# psoc4hv144k register map
Vendor: Infineon Technologies; Series: PSOC4HV144K; File version: 1.0
CPU: CM0PLUS r0p1, little endian, MPU, no FPU, VTOR, 2 interrupt priority bits, 25 interrupts
Registers are 32-bit, read-write, reset 0x0 unless marked. A register's access mark holds for its fields unless they carry their own. Offsets are from the block's base; [hi:lo] are bit positions; {n}, {i} and the like mark numbered series.

## HVSS — High Voltage Subsystem
Base 0x40060000
0x00 HVREG_STATUS ro
  [0] PWR_GOOD — High if regulator is settled and operating within normal limits
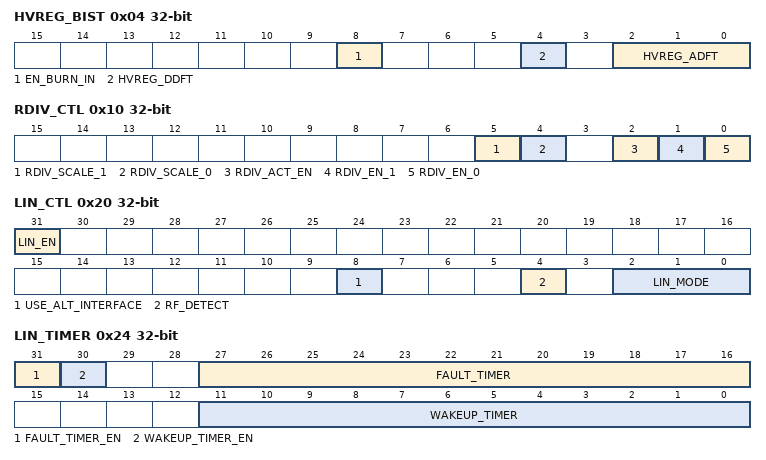
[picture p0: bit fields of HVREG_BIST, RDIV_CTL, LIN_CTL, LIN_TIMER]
0x04 HVREG_BIST
  [8] EN_BURN_IN — Enable burn-in test mode with Vccd(1.8V) domain
  [4] HVREG_DDFT — Enable HVREG DDFT outputs to DDFT interface when '1' (PG on ddft0, '0' on ddft1)
  [2:0] HVREG_ADFT — Controls ADFT switches
    0=NORMAL (Normal operation, amuxbus_a=Z); 1=BIAS_CIRCUIT_CURRENT_MONITOR (Bias current monitor (NMOS drain) on amuxbus_a); {v}=RSVD_{v} (N/A) (v=2..7)
0x10 RDIV_CTL — Resistor Attenuator Control
  [5] RDIV_SCALE_1 — VS1 attenuation 0=16X attenuation 1=24X attenuation
  [4] RDIV_SCALE_0 — VS0 attenuation 0=16X attenuation 1=24X attenuation
  [2] RDIV_ACT_EN — Power modes where RDIV is enabled 0=Enable in Active and Deep-Sleep modes 1=Enable in Active mode only
  [1] RDIV_EN_1 — Enable VS1 0=Disabled 1=Enabled during power modes selected by RDIVacten
  [0] RDIV_EN_0 — Enable VS0 0=Disabled 1=Enabled during power modes selected by RDIVacten
0x20 LIN_CTL — LIN Phy Control
  [31] LIN_EN — Master enable of the LIN interface. 0=Interface is reset and LIN pin is in Hi-Z state 1=Enable the LIN interface
  [8] USE_ALT_INTERFACE — Selects Primary or Alternate interface for Phy. The primary use is to enable compliance testing by directly manipulating the Phy interface through GPIOs. 0 = Primary interface (connected to internal LIN controller through HSIOM) 1 = Alternate interface (connected to GPIOs through HSIOM)
  [4] RF_DETECT — Renamed from SL_ROUND. 0=off; 1=on, reduce impact on LIN driver from incoming EMI.
  [2:0] LIN_MODE
    0=DISABLED (OFF (TX off, Rx off, Bias Circuits Off), LIN pin recessive); 1=SLEEP (TX off, RX on, LIN pin recessive (typically used in deep-sleep)); 2=STANDBY (TX off, RX off, Bias circuits on (faster turn-on, not normally used)); 3=DIAGNOSIS (TX on, RX on, TX w/weak pull-down (broken wire detect diag)); 4=NORMAL_1_0 (TX on, RX on, 1.0V/us TX edge rate, may not meet all parameters of LIN spec at some operating conditions); 5=NORMAL_1_5 (TX on, RX on, 1.5V/us TX edge rate, meets all parameters of LIN spec); 6=NORMAL_2_0 (TX on, RX on, 2.0V/us TX edge rate, may not meet all parameters of LIN spec at some operating conditions); 7=FAST (Fast mode (non-lin compliant, up to 100kb/s capable))
0x24 LIN_TIMER — LIN Timer Control
  [31] FAULT_TIMER_EN — Dominant state fault timer is running, req'd for full LIN compatibility
  [30] WAKEUP_TIMER_EN — Wakeup timer is running, required for full LIN compatibility if using Deep-sleep power mode
  [27:16] FAULT_TIMER — Number of LF_CLK edges before fault interrupt is triggered
  [11:0] WAKEUP_TIMER — Number of LF_CLK edges before wakeup interrupt is triggered
0x28 LIN_STATUS ro
  [0] LIN_RXD — Current state of LIN pin, except in lin_mode 0 or 2, when RXD = 1.
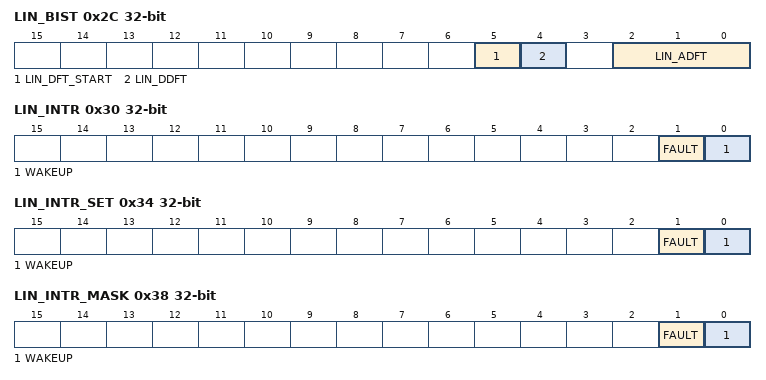
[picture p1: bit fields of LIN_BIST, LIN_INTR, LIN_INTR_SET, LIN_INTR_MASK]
0x2C LIN_BIST — LIN BIST Control
  [5] LIN_DFT_START — Delay line input
  [4] LIN_DDFT — Enable LIN DDFT outputs to DDFT interface ddft1 = dft<1>, ddft0 = dft<0>
  [2:0] LIN_ADFT — Enables Test Modes
    0=NORMAL (Normal Operation (DFT disabled), amuxbus_a=Z, dft<1:0>=0); 1=CURRENT_MONITOR_LWAVE (amuxbus_a=Iwave (PMOS drain), dft<1:0>=0); 2=VOLTAGE_MONITOR_ERRBUFF (amuxbus_a=ErrBuff, dft<1:0>=0); 3=WEAKOUTFET (OUTFET = 1/10, (amuxbus_a=Z, dft<1:0>=0)); 4=CURRENT_MONITOR_FORBIAS_CKT (amuxbus_a=Ibias monitor (PMOS drain), dft<1:0>=0); 5=SL_ROUND (0=Normal, 1=More moderate (rounded) edge for lower EMI); 6=DDFT_OSC (amuxbus_a = Z dft<1> = LIN_DFT_START, dft<0> = LIN_OSC); 7=DDFT_DELAY (amuxbus_a = Z dft<1> = LIN_DFT_START, dft<0> = LIN_DELAY)
0x30 LIN_INTR — LIN Interrupt Request Register
  [1] FAULT write-1-clears — Interface asserted state for too long (dominant state timeout)
  [0] WAKEUP write-1-clears — Master asserted dominant state wakeup (wakeup timer timeout)
0x34 LIN_INTR_SET — LIN Interrupt set register
  [1] FAULT write-1-sets — Write with '1' to set corresponding bit in interrupt request register.
  [0] WAKEUP write-1-sets — Write with '1' to set corresponding bit in interrupt request register.
0x38 LIN_INTR_MASK — LIN Interrupt mask register
  [1] FAULT — Mask bit for corresponding bit in interrupt request register.
  [0] WAKEUP — Mask bit for corresponding bit in interrupt request register.
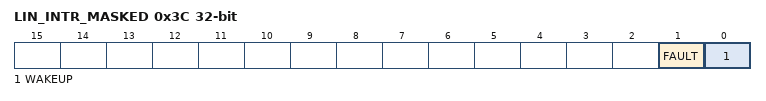
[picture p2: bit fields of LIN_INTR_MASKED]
0x3C LIN_INTR_MASKED ro — LIN Interrupt masked register
  [1] FAULT — Logical and of corresponding request and mask bits.
  [0] WAKEUP — Logical and of corresponding request and mask bits.
0x40 HVSS_DDFT — HVSS DDFT Control
  [0] LSOUT_DDFT — Enable LSOUT DDFT output to DDFT interface ddft1 = lsout_ddft, ddft0 = 0
0xFF00 HVREG_TRIM — HVREG Trim Settings, first byte
  [7:0] TRIM
0xFF04 LIN_TRIM — LIN Trim Settings
  [7:0] SLEW_CTL

## Notices in the file
(c) 2016-2026, Infineon Technologies AG or an affiliate of
Infineon Technologies AG.
SPDX-License-Identifier: Apache-2.0
Licensed under the Apache License, Version 2.0 (the "License");
you may not use this file except in compliance with the License.
You may obtain a copy of the License at
http://www.apache.org/licenses/LICENSE-2.0
Unless required by applicable law or agreed to in writing, software
distributed under the License is distributed on an "AS IS" BASIS,
WITHOUT WARRANTIES OR CONDITIONS OF ANY KIND, either express or implied.
See the License for the specific language governing permissions and
limitations under the License.
